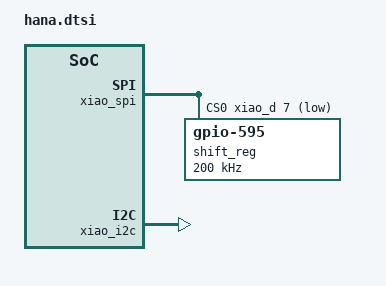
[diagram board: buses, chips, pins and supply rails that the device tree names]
#include "hana_matrix.dtsi"

&xiao_spi {
    status = "okay";
    cs-gpios = <&xiao_d 7 GPIO_ACTIVE_LOW>;
    shift_reg: 74HC595@0 {
        compatible = "zmk,gpio-595";
        status = "okay";
        gpio-controller;
        spi-max-frequency = <200000>;
        reg = <0>;
        #gpio-cells = <2>;
        ngpios = <8>;
    };
};

&xiao_serial { status = "disabled"; };

&xiao_i2c { status = "okay"; };
